# MCXA153 register map
Vendor: nxp.com; File version: 1.0
CPU: CM33 r2p0, little endian, no MPU, no FPU, VTOR, 3 interrupt priority bits
Registers are 32-bit, read-write, reset 0x0 unless marked. A register's access mark holds for its fields unless they carry their own. Offsets are from the block's base; [hi:lo] are bit positions; {n}, {i} and the like mark numbered series; 'fields as' and 'values as' point back to an identical list.

## OSTIMER0 — OSTIMER
Base 0x400AD000
0x00 EVTIMERL ro — EVTIMER Low
  [31:0] EVTIMER_COUNT_VALUE
0x04 EVTIMERH ro — EVTIMER High
  [9:0] EVTIMER_COUNT_VALUE
0x08 CAPTURE_L ro — Local Capture Low for CPU
  [31:0] CAPTURE_VALUE — EVTimer Capture Value
0x0C CAPTURE_H ro — Local Capture High for CPU
  [9:0] CAPTURE_VALUE — EVTimer Capture Value
0x10 MATCH_L reset 0xFFFFFFFF — Local Match Low for CPU
  [31:0] MATCH_VALUE — EVTimer Match Value
0x14 MATCH_H reset 0xFFFFFFFF — Local Match High for CPU
  [9:0] MATCH_VALUE — EVTimer Match Value
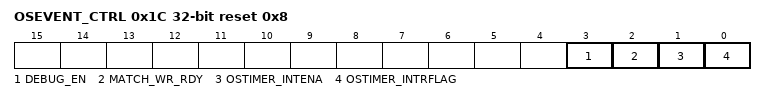
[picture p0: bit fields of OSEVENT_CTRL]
0x1C OSEVENT_CTRL reset 0x8 — OSTIMER Control for CPU
  [3] DEBUG_EN — Debug Enable
    0=DISABLE (Disables); 1=ENABLE (Enables)
  [2] MATCH_WR_RDY ro — EVTimer Match Write Ready
  [1] OSTIMER_INTENA — Interrupt or Wake-Up Request
    0=INTERRUPTS_BLOCKED; 1=INTERRUPTS_ENABLED
  [0] OSTIMER_INTRFLAG write-1-clears — Interrupt Flag

## WAKETIMER0 — WAKEUP_TIMER
Base 0x400AE000
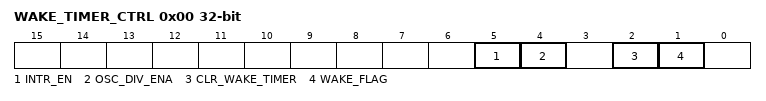
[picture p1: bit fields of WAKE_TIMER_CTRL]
0x00 WAKE_TIMER_CTRL — Wake Timer Control
  [5] INTR_EN — Enable Interrupt
    0=DISABLE (Disabled); 1=ENABLE (Enabled)
  [4] OSC_DIV_ENA — OSC Divide Enable
    0=DISABLE (Disabled); 1=ENABLE (Enabled)
  [2] CLR_WAKE_TIMER wo — Clear Wake Timer
    0=DISABLE (No effect.); 1=ENABLE (Clears the wake timer counter and halts operation until a new count value is loaded.)
  [1] WAKE_FLAG write-1-clears — Wake Timer Status Flag
    0=DISABLE (Wake timer has not timed out.); 1=ENABLE (Wake timer has timed out.)
0x0C WAKE_TIMER_CNT — Wake Timer Counter
  [31:0] WAKE_CNT — Wake Counter

## PORT0 — PORT
Base 0x400BC000
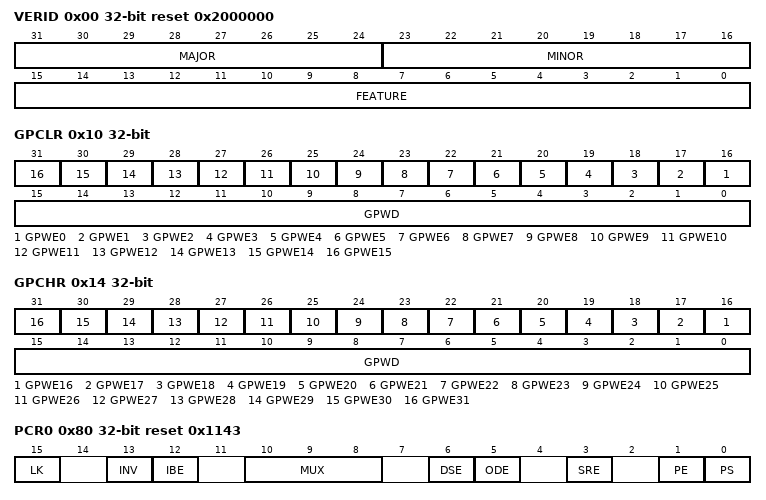
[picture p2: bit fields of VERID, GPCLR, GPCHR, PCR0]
0x00 VERID ro reset 0x2000000 — Version ID
  [31:24] MAJOR — Major Version Number
  [23:16] MINOR — Minor Version Number
  [15:0] FEATURE — Feature Specification Number
    0=Basic implementation
0x10 GPCLR — Global Pin Control Low
  [n+16] GPWE{n} (n=0..15) — Global Pin Write Enable
    0=gpwe0 (Not updated); 1=gpwe1 (Updated)
  [15:0] GPWD — Global Pin Write Data
0x14 GPCHR — Global Pin Control High
  [n] GPWE{n} (n=16..31) — Global Pin Write Enable
    0=gpwe0 (Not updated); 1=gpwe1 (Updated)
  [15:0] GPWD — Global Pin Write Data
0x20 CONFIG — Configuration
  [0] RANGE — Port Voltage Range
    0=1.71 V-3.6 V; 1=2.70 V-3.6 V
0x80 PCR0 reset 0x1143 — Pin Control 0
  [15] LK — Lock Register
    0=Does not lock; 1=Locks
  [13] INV — Invert Input
    0=Does not invert; 1=Inverts
  [12] IBE — Input Buffer Enable
    0=Disables; 1=Enables
  [10:8] MUX — Pin Multiplex Control
    0=Alternative 0 (GPIO); {v}=Alternative {v} (chip-specific) (v=1..7)
  [6] DSE — Drive Strength Enable
    0=Low; 1=High
  [5] ODE — Open Drain Enable
    0=Disables; 1=Enables
  [3] SRE — Slew Rate Enable
    0=Fast; 1=Slow
  [1] PE — Pull Enable
    0=Disables; 1=Enables
  [0] PS — Pull Select
    0=Enables internal pulldown resistor; 1=Enables internal pullup resistor
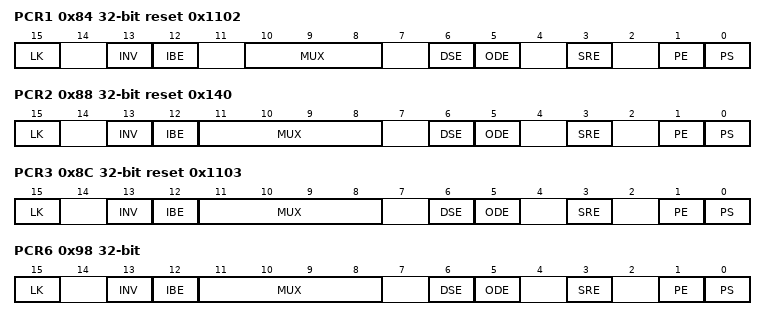
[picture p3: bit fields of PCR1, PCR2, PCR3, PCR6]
0x84 PCR1 reset 0x1102 — Pin Control 1
  fields as PCR0
0x88 PCR2 reset 0x140 — Pin Control 2
  [15] LK — Lock Register
    0=Does not lock; 1=Locks
  [13] INV — Invert Input
    0=Does not invert; 1=Inverts
  [12] IBE — Input Buffer Enable
    0=Disables; 1=Enables
  [11:8] MUX — Pin Multiplex Control
    0=Alternative 0 (GPIO); {v}=Alternative {v} (chip-specific) (v=1..12)
  [6] DSE — Drive Strength Enable
    0=Low; 1=High
  [5] ODE — Open Drain Enable
    0=Disables; 1=Enables
  [3] SRE — Slew Rate Enable
    0=Fast; 1=Slow
  [1] PE — Pull Enable
    0=Disables; 1=Enables
  [0] PS — Pull Select
    values as PCR0.PS
0x8C PCR3 reset 0x1103 — Pin Control 3
  fields as PCR2
0x98 PCR6 — Pin Control 6
  fields as PCR2
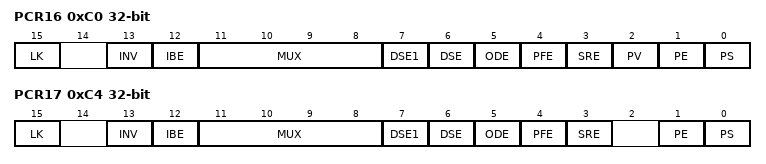
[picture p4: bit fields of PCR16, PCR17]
0xC0 PCR16 — Pin Control 16
  [15] LK — Lock Register
    0=Does not lock; 1=Locks
  [13] INV — Invert Input
    0=Does not invert; 1=Inverts
  [12] IBE — Input Buffer Enable
    0=Disables; 1=Enables
  [11:8] MUX — Pin Multiplex Control
    values as PCR2.MUX
  [7] DSE1 — Drive Strength Enable
    0=Normal; 1=Double
  [6] DSE — Drive Strength Enable
    0=Low; 1=High
  [5] ODE — Open Drain Enable
    0=Disables; 1=Enables
  [4] PFE — Passive Filter Enable
    0=Disables; 1=Enables
  [3] SRE — Slew Rate Enable
    0=Fast; 1=Slow
  [2] PV — Pull Value
    0=Low; 1=High
  [1] PE — Pull Enable
    0=Disables; 1=Enables
  [0] PS — Pull Select
    values as PCR0.PS
0xC4 PCR17 — Pin Control 17
  [15] LK — Lock Register
    0=Does not lock; 1=Locks
  [13] INV — Invert Input
    0=Does not invert; 1=Inverts
  [12] IBE — Input Buffer Enable
    0=Disables; 1=Enables
  [11:8] MUX — Pin Multiplex Control
    values as PCR2.MUX
  [7] DSE1 — Drive Strength Enable
    0=Normal; 1=Double
  [6] DSE — Drive Strength Enable
    0=Low; 1=High
  [5] ODE — Open Drain Enable
    0=Disables; 1=Enables
  [4] PFE — Passive Filter Enable
    0=Disables; 1=Enables
  [3] SRE — Slew Rate Enable
    0=Fast; 1=Slow
  [1] PE — Pull Enable
    0=Disables; 1=Enables
  [0] PS — Pull Select
    values as PCR0.PS
